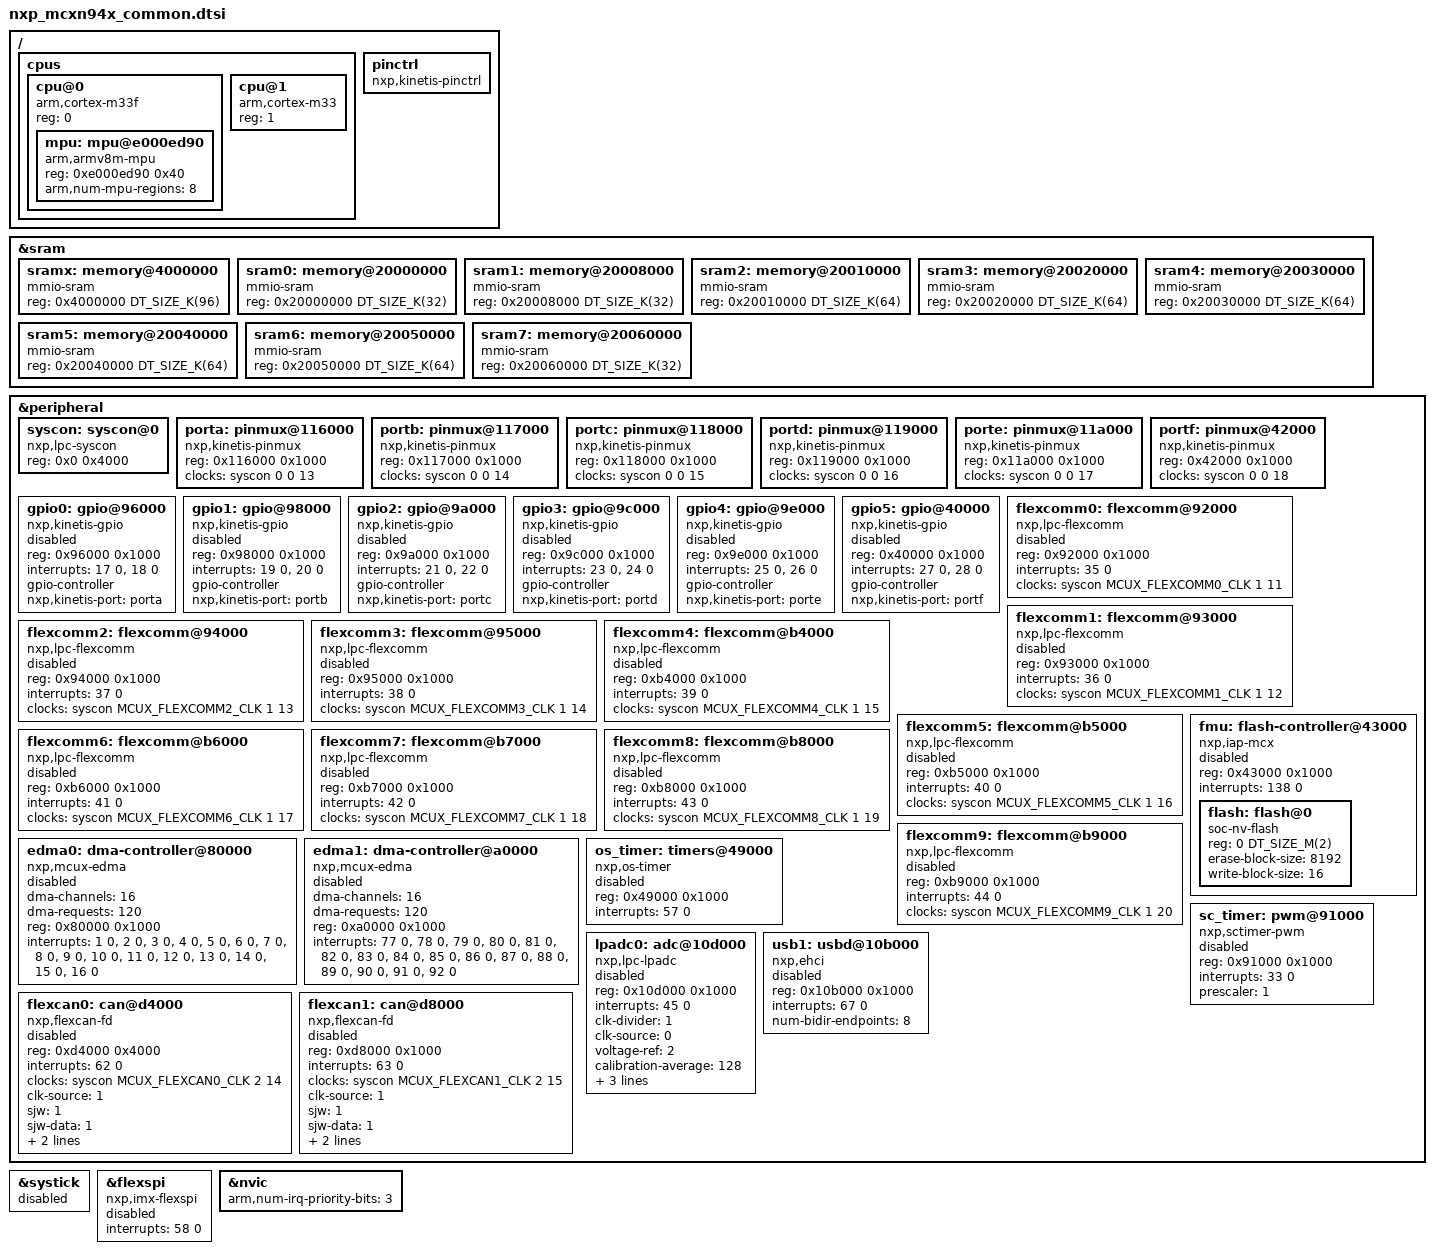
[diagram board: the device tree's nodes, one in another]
/*
 * Copyright 2023 NXP
 *
 * SPDX-License-Identifier: Apache-2.0
 */

#include <mem.h>
#include <zephyr/dt-bindings/clock/mcux_lpc_syscon_clock.h>
#include <zephyr/dt-bindings/gpio/gpio.h>
#include <arm/armv8-m.dtsi>

/ {
	cpus: cpus {
		#address-cells = <1>;
		#size-cells = <0>;

		cpu@0 {
			compatible = "arm,cortex-m33f";
			reg = <0>;
			#address-cells = <1>;
			#size-cells = <1>;

			mpu: mpu@e000ed90 {
				compatible = "arm,armv8m-mpu";
				reg = <0xe000ed90 0x40>;
				arm,num-mpu-regions = <8>;
			};
		};
		cpu@1 {
			compatible = "arm,cortex-m33";
			reg = <1>;
		};
	};

	/* Dummy pinctrl node, filled with pin mux options at board level */
	pinctrl: pinctrl {
		compatible = "nxp,kinetis-pinctrl";
		status = "okay";
	};
};

&sram {
	#address-cells = <1>;
	#size-cells = <1>;

	sramx: memory@4000000 {
		compatible = "mmio-sram";
		reg = <0x4000000 DT_SIZE_K(96)>;
	};

	/* mcxn94x Memory configurations:
	 *
	 * RAM blocks RAMA through SRAM4 are contiguous address ranges
	 *
	 * MCXN94X: 512KB RAM, RAMX: 96K, RAMA: 32K, RAMB: 32K,
	 *                     RAMC: 64K, RAMD: 64K, RAME: 64K
	 *                     RAMF: 64K, RAMG: 64K, RAMH: 32K
	 */
	sram0: memory@20000000 {
		compatible = "mmio-sram";
		reg = <0x20000000 DT_SIZE_K(32)>;
	};

	sram1: memory@20008000 {
		compatible = "mmio-sram";
		reg = <0x20008000 DT_SIZE_K(32)>;
	};

	sram2: memory@20010000 {
		compatible = "mmio-sram";
		reg = <0x20010000 DT_SIZE_K(64)>;
	};

	sram3: memory@20020000 {
		compatible = "mmio-sram";
		reg = <0x20020000 DT_SIZE_K(64)>;
	};

	sram4: memory@20030000 {
		compatible = "mmio-sram";
		reg = <0x20030000  DT_SIZE_K(64)>;
	};

	sram5: memory@20040000 {
		compatible = "mmio-sram";
		reg = <0x20040000  DT_SIZE_K(64)>;
	};

	sram6: memory@20050000 {
		compatible = "mmio-sram";
		reg = <0x20050000  DT_SIZE_K(64)>;
	};

	sram7: memory@20060000 {
		compatible = "mmio-sram";
		reg = <0x20060000  DT_SIZE_K(32)>;
	};
};

&peripheral {
	#address-cells = <1>;
	#size-cells = <1>;

	syscon: syscon@0 {
		compatible = "nxp,lpc-syscon";
		reg = <0x0 0x4000>;
		#clock-cells = <3>;
	};

	porta: pinmux@116000 {
		compatible = "nxp,kinetis-pinmux";
		reg = <0x116000 0x1000>;
		clocks = <&syscon 0 0 13>;
	};

	portb: pinmux@117000 {
		compatible = "nxp,kinetis-pinmux";
		reg = <0x117000 0x1000>;
		clocks = <&syscon 0 0 14>;
	};

	portc: pinmux@118000 {
		compatible = "nxp,kinetis-pinmux";
		reg = <0x118000 0x1000>;
		clocks = <&syscon 0 0 15>;
	};

	portd: pinmux@119000 {
		compatible = "nxp,kinetis-pinmux";
		reg = <0x119000 0x1000>;
		clocks = <&syscon 0 0 16>;
	};

	porte: pinmux@11a000 {
		compatible = "nxp,kinetis-pinmux";
		reg = <0x11a000 0x1000>;
		clocks = <&syscon 0 0 17>;
	};

	portf: pinmux@42000 {
		compatible = "nxp,kinetis-pinmux";
		reg = <0x42000 0x1000>;
		clocks = <&syscon 0 0 18>;
	};

	gpio0: gpio@96000 {
		compatible = "nxp,kinetis-gpio";
		status = "disabled";
		reg = <0x96000 0x1000>;
		interrupts = <17 0>,<18 0>;
		gpio-controller;
		#gpio-cells = <2>;
		nxp,kinetis-port = <&porta>;
	};

	gpio1: gpio@98000 {
		compatible = "nxp,kinetis-gpio";
		status = "disabled";
		reg = <0x98000 0x1000>;
		interrupts = <19 0>,<20 0>;
		gpio-controller;
		#gpio-cells = <2>;
		nxp,kinetis-port = <&portb>;
	};

	gpio2: gpio@9a000 {
		compatible = "nxp,kinetis-gpio";
		status = "disabled";
		reg = <0x9a000 0x1000>;
		interrupts = <21 0>,<22 0>;
		gpio-controller;
		#gpio-cells = <2>;
		nxp,kinetis-port = <&portc>;
	};

	gpio3: gpio@9c000 {
		compatible = "nxp,kinetis-gpio";
		status = "disabled";
		reg = <0x9c000 0x1000>;
		interrupts = <23 0>,<24 0>;
		gpio-controller;
		#gpio-cells = <2>;
		nxp,kinetis-port = <&portd>;
	};

	gpio4: gpio@9e000 {
		compatible = "nxp,kinetis-gpio";
		status = "disabled";
		reg = <0x9e000 0x1000>;
		interrupts = <25 0>,<26 0>;
		gpio-controller;
		#gpio-cells = <2>;
		nxp,kinetis-port = <&porte>;
	};

	gpio5: gpio@40000 {
		compatible = "nxp,kinetis-gpio";
		status = "disabled";
		reg = <0x40000 0x1000>;
		interrupts = <27 0>,<28 0>;
		gpio-controller;
		#gpio-cells = <2>;
		nxp,kinetis-port = <&portf>;
	};

	flexcomm0: flexcomm@92000 {
		compatible = "nxp,lpc-flexcomm";
		reg = <0x92000 0x1000>;
		interrupts = <35 0>;
		clocks = <&syscon MCUX_FLEXCOMM0_CLK 1 11>;
		status = "disabled";
	};

	flexcomm1: flexcomm@93000 {
		compatible = "nxp,lpc-flexcomm";
		reg = <0x93000 0x1000>;
		interrupts = <36 0>;
		clocks = <&syscon MCUX_FLEXCOMM1_CLK 1 12>;
		status = "disabled";
	};

	flexcomm2: flexcomm@94000 {
		compatible = "nxp,lpc-flexcomm";
		reg = <0x94000 0x1000>;
		interrupts = <37 0>;
		clocks = <&syscon MCUX_FLEXCOMM2_CLK 1 13>;
		status = "disabled";
	};

	flexcomm3: flexcomm@95000 {
		compatible = "nxp,lpc-flexcomm";
		reg = <0x95000 0x1000>;
		interrupts = <38 0>;
		clocks = <&syscon MCUX_FLEXCOMM3_CLK 1 14>;
		status = "disabled";
	};

	flexcomm4: flexcomm@b4000 {
		compatible = "nxp,lpc-flexcomm";
		reg = <0xb4000 0x1000>;
		interrupts = <39 0>;
		clocks = <&syscon MCUX_FLEXCOMM4_CLK 1 15>;
		status = "disabled";
	};

	flexcomm5: flexcomm@b5000 {
		compatible = "nxp,lpc-flexcomm";
		reg = <0xb5000 0x1000>;
		interrupts = <40 0>;
		clocks = <&syscon MCUX_FLEXCOMM5_CLK 1 16>;
		status = "disabled";
	};

	flexcomm6: flexcomm@b6000 {
		compatible = "nxp,lpc-flexcomm";
		reg = <0xb6000 0x1000>;
		interrupts = <41 0>;
		clocks = <&syscon MCUX_FLEXCOMM6_CLK 1 17>;
		status = "disabled";
	};

	flexcomm7: flexcomm@b7000 {
		compatible = "nxp,lpc-flexcomm";
		reg = <0xb7000 0x1000>;
		interrupts = <42 0>;
		clocks = <&syscon MCUX_FLEXCOMM7_CLK 1 18>;
		status = "disabled";
	};

	flexcomm8: flexcomm@b8000 {
		compatible = "nxp,lpc-flexcomm";
		reg = <0xb8000 0x1000>;
		interrupts = <43 0>;
		clocks = <&syscon MCUX_FLEXCOMM8_CLK 1 19>;
		status = "disabled";
	};

	flexcomm9: flexcomm@b9000 {
		compatible = "nxp,lpc-flexcomm";
		reg = <0xb9000 0x1000>;
		interrupts = <44 0>;
		clocks = <&syscon MCUX_FLEXCOMM9_CLK 1 20>;
		status = "disabled";
	};

	edma0: dma-controller@80000 {
		#dma-cells = <2>;
		compatible = "nxp,mcux-edma";
		dma-channels = <16>;
		dma-requests = <120>;

		reg = <0x80000 0x1000>;
		interrupts = <1 0>, <2 0>, <3 0>, <4 0>,
			<5 0>, <6 0>, <7 0>, <8 0>,
			<9 0>, <10 0>, <11 0>, <12 0>,
			<13 0>, <14 0>, <15 0>, <16 0>;
		status = "disabled";
	};

	edma1: dma-controller@a0000 {
		#dma-cells = <2>;
		compatible = "nxp,mcux-edma";
		dma-channels = <16>;
		dma-requests = <120>;

		reg = <0xa0000 0x1000>;
		interrupts = <77 0>, <78 0>, <79 0>, <80 0>,
			<81 0>, <82 0>, <83 0>, <84 0>,
			<85 0>, <86 0>, <87 0>, <88 0>,
			<89 0>, <90 0>, <91 0>, <92 0>;
		status = "disabled";
	};

	fmu: flash-controller@43000 {
		compatible = "nxp,iap-mcx";
		reg = <0x43000 0x1000>;
		interrupts = <138 0>;
		status = "disabled";

		#address-cells = <1>;
		#size-cells = <1>;

		flash: flash@0 {
			compatible = "soc-nv-flash";
			reg = <0 DT_SIZE_M(2)>;
			erase-block-size = <8192>;
			write-block-size = <16>;
		};
	};

	os_timer: timers@49000 {
		compatible = "nxp,os-timer";
		reg = <0x49000 0x1000>;
		interrupts = <57 0>;
		status = "disabled";
	};

	sc_timer: pwm@91000 {
		compatible = "nxp,sctimer-pwm";
		reg = <0x91000 0x1000>;
		interrupts = <33 0>;
		status = "disabled";
		prescaler = <1>;
		#pwm-cells = <3>;
	};

	lpadc0: adc@10d000 {
		compatible = "nxp,lpc-lpadc";
		reg = <0x10d000 0x1000>;
		interrupts = <45 0>;
		status = "disabled";
		clk-divider = <1>;
		clk-source = <0>;
		voltage-ref= <2>;
		calibration-average = <128>;
		power-level = <0>;
		offset-value-a = <0x10>;
		offset-value-b = <0x10>;
		#io-channel-cells = <1>;
	};

	usb1: usbd@10b000 {
		compatible = "nxp,ehci";
		reg = <0x10b000 0x1000>;
		interrupts = <67 0>;
		interrupt-names = "usb_otg";
		num-bidir-endpoints = <8>;
		status = "disabled";
	};

	flexcan0: can@d4000 {
		compatible = "nxp,flexcan-fd", "nxp,flexcan";
		reg = <0xd4000 0x4000>;
		interrupts = <62 0>;
		interrupt-names = "common";
		clocks = <&syscon MCUX_FLEXCAN0_CLK 2 14>;
		clk-source = <1>;
		sjw = <1>;
		sjw-data = <1>;
		sample-point = <875>;
		sample-point-data = <875>;
		status = "disabled";
	};

	flexcan1: can@d8000 {
		compatible = "nxp,flexcan-fd", "nxp,flexcan";
		reg = <0xd8000 0x1000>;
		interrupts = <63 0>;
		interrupt-names = "common";
		clocks = <&syscon MCUX_FLEXCAN1_CLK 2 15>;
		clk-source = <1>;
		sjw = <1>;
		sjw-data = <1>;
		sample-point = <875>;
		sample-point-data = <875>;
		status = "disabled";
	};
};

&systick {
	/*
	 * MCXN94X relies by default on the OS Timer for system clock
	 * implementation, so the SysTick node is not to be enabled.
	 */
	status = "disabled";
};

&flexspi {
	compatible = "nxp,imx-flexspi";
	interrupts = <58 0>;
	#address-cells = <1>;
	#size-cells = <0>;
	status = "disabled";
};

&nvic {
	arm,num-irq-priority-bits = <3>;
};
